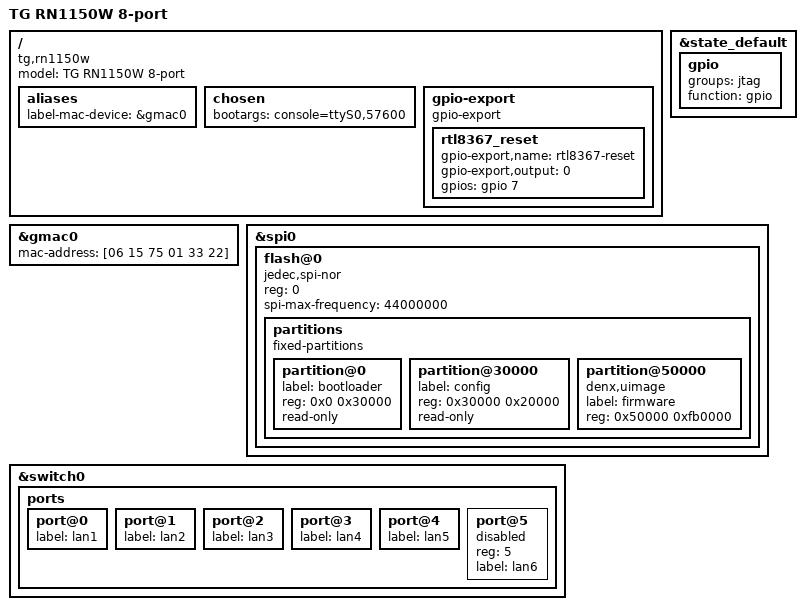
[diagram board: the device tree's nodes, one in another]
// SPDX-License-Identifier: GPL-2.0-or-later
//
// TG RN1150W / "MT7621 千兆有线路由器" 8 口白牌机
// MT7621AT + MT7530(内部 5 个 PHY) + RTL8367SB(外挂 4 口)
// RTL8367SB 复位脚 = GPIO7 (厂商内核: "GPIO7 set to high / clear to low")
//
// v2 (8 口实测后修正): RTL8367SB 级联在 MT7530 的 PHY0 (lan1) 上, 不是 port5。
//     面板 1..4 = lan5/lan4/lan3/lan2 (MT7530 直连)
//     面板 5..8 = lan1 (RTL 的 4 个口共用这条 1G 上行)
//     RTL8367SB 保持出厂非管理型交换机状态, 只由 GPIO7 释放复位。
//     port5 为幽灵口, 保持 disabled。

#include "mt7621.dtsi"

#include <dt-bindings/gpio/gpio.h>
#include <dt-bindings/input/input.h>
#include <dt-bindings/leds/common.h>

/ {
	compatible = "tg,rn1150w", "mediatek,mt7621-soc";
	model = "TG RN1150W 8-port";

	aliases {
		label-mac-device = &gmac0;
	};

	chosen {
		bootargs = "console=ttyS0,57600";
	};

	/* 释放 RTL8367SB 复位。厂商序列是 拉高->拉低, 即高电平复位、低电平工作。
	 * 若刷机后发现 lan6 段(外挂 3 口)不通, 先把 output 改成 <1> 试试。 */
	gpio-export {
		compatible = "gpio-export";
		#size-cells = <0>;

		rtl8367_reset {
			gpio-export,name = "rtl8367-reset";
			gpio-export,output = <0>;
			gpios = <&gpio 7 GPIO_ACTIVE_HIGH>;
		};
	};
};

&gmac0 {
	/* Breed 里读到的 LAN MAC, 固定住避免每次启动变成随机地址 */
	mac-address = [06 15 75 01 33 22];
};

/* GPIO7 在 MT7621 上默认是 JTAG 功能，必须切回 GPIO，
 * 否则 gpio-export 申请不到，RTL8367SB 一直处于复位。 */
&state_default {
	gpio {
		groups = "jtag";
		function = "gpio";
	};
};

&spi0 {
	status = "okay";

	flash@0 {
		compatible = "jedec,spi-nor";
		reg = <0>;
		spi-max-frequency = <44000000>;

		partitions {
			compatible = "fixed-partitions";
			#address-cells = <1>;
			#size-cells = <1>;

			/* 0x00000-0x20000 Breed, 0x20000-0x50000 保留 */
			partition@0 {
				label = "bootloader";
				reg = <0x0 0x30000>;
				read-only;
			};

			partition@30000 {
				label = "config";
				reg = <0x30000 0x20000>;
				read-only;
			};

			/* 与 Breed 的「公版 0x50000」布局严格对齐。
			 * compatible = "denx,uimage" 必须保留：内核靠它把这段拆成
			 * kernel + rootfs，缺了会 panic 在 "Unable to mount root fs"。 */
			partition@50000 {
				compatible = "denx,uimage";
				label = "firmware";
				reg = <0x50000 0xfb0000>;
			};
		};
	};
};

&switch0 {
	ports {
		/* MT7530 的 5 个内置 PHY */
		port@0 {
			status = "okay";
			label = "lan1";
		};

		port@1 {
			status = "okay";
			label = "lan2";
		};

		port@2 {
			status = "okay";
			label = "lan3";
		};

		port@3 {
			status = "okay";
			label = "lan4";
		};

		port@4 {
			status = "okay";
			label = "lan5";
		};

		/* port5 (MT7530 第二个 GMAC) 实测未使用: 8 口实测证明 RTL8367SB
		 * 是级联在 PHY0 (lan1) 上的, 面板 5/6/7/8 = RTL 的 4 个口, 共享
		 * lan1 这条 1G 上行。port5 保持 disabled, 不再暴露幽灵接口 lan6。 */
		port@5 {
			status = "disabled";
			reg = <5>;
			label = "lan6";
		};
	};
};
